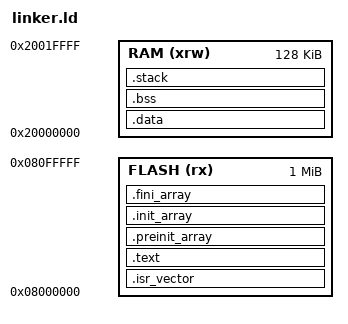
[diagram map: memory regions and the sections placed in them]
ENTRY(Reset_Handler)

MEMORY
{
  FLASH (rx) : ORIGIN = 0x08000000, LENGTH = 1024K
  RAM (xrw)  : ORIGIN = 0x20000000, LENGTH = 128K
}

SECTIONS
{
  .isr_vector :
  {
    KEEP(*(.isr_vector))
  } >FLASH

  .text :
  {
    . = ALIGN(4);
    *(.text*)
    *(.rodata*)
    *(.glue_7)
    *(.glue_7t)
    KEEP(*(.init))
    KEEP(*(.fini))
    /* C++ exception unwinding tables */
    *(.ARM.extab* .gnu.linkonce.armextab.*)
    *(.ARM.exidx* .gnu.linkonce.armexidx.*)
    KEEP(*(.eh_frame))
  } >FLASH

  /* C/C++ init/fini arrays in FLASH */
  .preinit_array :
  {
    PROVIDE_HIDDEN (__preinit_array_start = .);
    KEEP (*(.preinit_array*))
    PROVIDE_HIDDEN (__preinit_array_end = .);
  } >FLASH

  .init_array :
  {
    PROVIDE_HIDDEN (__init_array_start = .);
    KEEP (*(SORT(.init_array.*)))
    KEEP (*(.init_array*))
    PROVIDE_HIDDEN (__init_array_end = .);
  } >FLASH

  .fini_array :
  {
    PROVIDE_HIDDEN (__fini_array_start = .);
    KEEP (*(SORT(.fini_array.*)))
    KEEP (*(.fini_array*))
    PROVIDE_HIDDEN (__fini_array_end = .);
  } >FLASH

  /* End of code region in FLASH; start of load image for .data */
  __etext = .;

  .data : AT (__etext)
  {
    __data_start__ = .;
    *(.data*)
    __data_end__ = .;
  } >RAM

  .bss :
  {
    __bss_start__ = .;
    *(.bss*)
    *(COMMON)
    . = ALIGN(4);
    __bss_end__ = .;
    end = .;
    _end = .;
  } >RAM

  .stack :
  {
    . = ALIGN(8);
    _stack = .;
    . += 0x400;
  } >RAM
}
